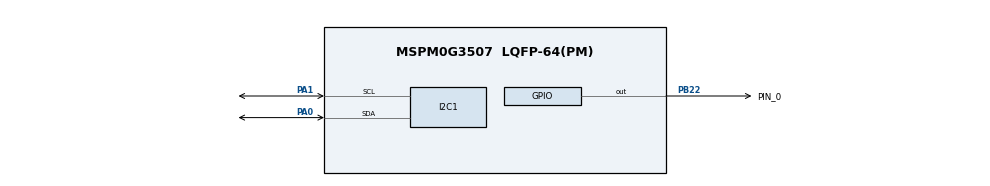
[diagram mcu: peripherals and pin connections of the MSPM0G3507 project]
/**
 * These arguments were used when this file was generated. They will be automatically applied on subsequent loads
 * via the GUI or CLI. Run CLI with '--help' for additional information on how to override these arguments.
 * @cliArgs --device "MSPM0G350X" --part "Default" --package "LQFP-64(PM)" --product "mspm0_sdk@2.10.00.04"
 * @v2CliArgs --device "MSPM0G3507" --package "LQFP-64(PM)" --product "mspm0_sdk@2.10.00.04"
 * @versions {"tool":"1.26.2+4477"}
 */

/**
 * Import the modules used in this configuration.
 */
const GPIO          = scripting.addModule("/ti/driverlib/GPIO", {}, false);
const GPIO1         = GPIO.addInstance();
const I2C           = scripting.addModule("/ti/driverlib/I2C", {}, false);
const I2C1          = I2C.addInstance();
const SYSCTL        = scripting.addModule("/ti/driverlib/SYSCTL");
const SYSTICK       = scripting.addModule("/ti/driverlib/SYSTICK");
const TIMER         = scripting.addModule("/ti/driverlib/TIMER", {}, false);
const TIMER1        = TIMER.addInstance();
const UART          = scripting.addModule("/ti/driverlib/UART", {}, false);
const UART1         = UART.addInstance();
const ProjectConfig = scripting.addModule("/ti/project_config/ProjectConfig");

/**
 * Write custom configuration values to the imported modules.
 */
const divider9       = system.clockTree["UDIV"];
divider9.divideValue = 2;

const mux4       = system.clockTree["EXHFMUX"];
mux4.inputSelect = "EXHFMUX_XTAL";

const mux8       = system.clockTree["HSCLKMUX"];
mux8.inputSelect = "HSCLKMUX_SYSPLL2X";

const mux12       = system.clockTree["SYSPLLMUX"];
mux12.inputSelect = "zSYSPLLMUX_HFCLK";

const pinFunction4       = system.clockTree["HFXT"];
pinFunction4.inputFreq   = 40;
pinFunction4.HFXTStartup = 10;
pinFunction4.enable      = true;

GPIO1.$name                              = "User_led";
GPIO1.associatedPins[0].$name            = "PIN_0";
GPIO1.associatedPins[0].internalResistor = "PULL_DOWN";
GPIO1.associatedPins[0].pin.$assign      = "PB22";

const Board = scripting.addModule("/ti/driverlib/Board", {}, false);

I2C1.$name                           = "I2C_0";
I2C1.basicEnableController           = true;
I2C1.advDigitalGlitchFilter          = "CLOCKS_1";
I2C1.enableDMAEvent1                 = false;
I2C1.enableDMAEvent2                 = false;
I2C1.basicTargetSecAddressEnable     = true;
I2C1.basicEnableTarget               = true;
I2C1.basicControllerStandardBusSpeed = "Fast";
I2C1.peripheral.$assign              = "I2C0";
I2C1.peripheral.sdaPin.$assign       = "PA0";
I2C1.peripheral.sclPin.$assign       = "PA1";
I2C1.sdaPinConfig.$name              = "ti_driverlib_gpio_GPIOPinGeneric0";
I2C1.sclPinConfig.$name              = "ti_driverlib_gpio_GPIOPinGeneric1";

SYSCTL.clockTreeEn = true;

SYSTICK.periodEnable    = true;
SYSTICK.interruptEnable = true;
SYSTICK.systickEnable   = true;
SYSTICK.period          = 80000;

TIMER1.$name              = "TIMER_0_counter";
TIMER1.timerClkPrescale   = 100;
TIMER1.timerMode          = "PERIODIC";
TIMER1.timerPeriod        = "1ms";
TIMER1.timerStartTimer    = true;
TIMER1.interrupts         = ["ZERO"];
TIMER1.interruptPriority  = "1";
TIMER1.peripheral.$assign = "TIMG0";

UART1.$name                             = "UART_0";
UART1.targetBaudRate                    = 115200;
UART1.enableFIFO                        = true;
UART1.rxFifoThreshold                   = "DL_UART_RX_FIFO_LEVEL_ONE_ENTRY";
UART1.enabledInterrupts                 = ["DMA_DONE_RX","DMA_DONE_TX"];
UART1.enabledDMARXTriggers              = "DL_UART_DMA_INTERRUPT_RX";
UART1.enabledDMATXTriggers              = "DL_UART_DMA_INTERRUPT_TX";
UART1.txPinConfig.$name                 = "ti_driverlib_gpio_GPIOPinGeneric2";
UART1.rxPinConfig.$name                 = "ti_driverlib_gpio_GPIOPinGeneric3";
UART1.DMA_CHANNEL_RX.$name              = "DMA_CH0";
UART1.DMA_CHANNEL_RX.addressMode        = "f2b";
UART1.DMA_CHANNEL_RX.srcLength          = "BYTE";
UART1.DMA_CHANNEL_RX.dstLength          = "BYTE";
UART1.DMA_CHANNEL_RX.transferMode       = "FULL_CH_REPEAT_SINGLE";
UART1.DMA_CHANNEL_RX.peripheral.$assign = "DMA_CH0";
UART1.DMA_CHANNEL_TX.$name              = "DMA_CH1";
UART1.DMA_CHANNEL_TX.enableInterrupt    = true;
UART1.DMA_CHANNEL_TX.srcLength          = "BYTE";
UART1.DMA_CHANNEL_TX.addressMode        = "b2f";
UART1.DMA_CHANNEL_TX.dstLength          = "BYTE";
UART1.DMA_CHANNEL_TX.peripheral.$assign = "DMA_CH1";

ProjectConfig.genLibCMSIS = true;

/**
 * Pinmux solution for unlocked pins/peripherals. This ensures that minor changes to the automatic solver in a future
 * version of the tool will not impact the pinmux you originally saw.  These lines can be completely deleted in order to
 * re-solve from scratch.
 */
pinFunction4.peripheral.$suggestSolution           = "SYSCTL";
pinFunction4.peripheral.hfxInPin.$suggestSolution  = "PA5";
pinFunction4.peripheral.hfxOutPin.$suggestSolution = "PA6";
Board.peripheral.$suggestSolution                  = "DEBUGSS";
Board.peripheral.swclkPin.$suggestSolution         = "PA20";
Board.peripheral.swdioPin.$suggestSolution         = "PA19";
UART1.peripheral.$suggestSolution                  = "UART0";
UART1.peripheral.rxPin.$suggestSolution            = "PA11";
UART1.peripheral.txPin.$suggestSolution            = "PA10";
